# YT9215 register map
Vendor: Motorcomm; Series: YT921x; File version: 1.0
Motorcomm YT921x Gigabit Ethernet switch family, YT9215 family (YT9215SC, YT9215S, YT9215RB, YT9214NB, YT9213NB). The addresses are those of the switch register space, which a host reaches indirectly over MDIO; they are not memory mapped.
Registers are 32-bit, read-write, no defined reset value unless marked. A register's access mark holds for its fields unless they carry their own. Offsets are from the block's base; lines under a group give offsets from that group; [hi:lo] are bit positions; {n}, {i} and the like mark numbered series; 'fields as' and 'values as' point back to an identical list; <NAME> marks a mode.

## Memory map
0x0006A000 EXT_MBUS size 0x10 — External MDIO master
0x00080000 GLOBAL size 0xB00C — Global control and port MACs
0x000A0000 EEE_MAC size 0x284 — Per-port EEE
0x000B0000 EEE size 0x4 — EEE control
0x000C0000 MIB size 0xC00 — Port counters
0x000D0000 LED size 0x1F8 — LED control
0x000E0000 EDATA size 0x44 — Configuration byte store and clock
0x000F0000 INT_MBUS size 0x10 — Internal MDIO master
0x00100000 EGRESS size 0x310 — Egress tag processing
0x00180000 L2 size 0x10000 — Layer 2 forwarding and VLAN table
0x001C0000 ACL_ACTION size 0x17FC — ACL action table
0x00200000 ACL size 0x5F80 — ACL keys and control
0x00210000 PARSER size 0xD4 — Ingress parser
0x00220000 METER size 0x1258 — Ingress meters
0x00230000 PORT_VLAN size 0xAC — Ingress port VLAN
0x00300000 QUEUE size 0x304 — Queue manager
0x00340000 SCHED size 0x1602C — Egress scheduler

## EXT_MBUS — External MDIO master
Base 0x0006A000
0x00 EXT_MBUS_OP — Starts a transfer on the external MDIO master and shows when it has finished; see MDIO master transfer.
  [0] START — Write 1 to start the transfer set up in EXT_MBUS_CTRL. Reads 1 until the transfer is complete.
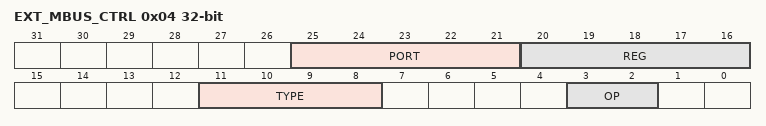
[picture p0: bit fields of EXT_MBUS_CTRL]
0x04 EXT_MBUS_CTRL — Address and direction of the next transfer on the external MDIO pins.
  [25:21] PORT — PHY address from 0 to 31. On the internal bus it equals the port number.
  [20:16] REG — PHY register number from 0 to 31.
  [11:8] TYPE — Frame format. The comment on the field reads "wild guess", so the width of the field is inferred.
    4=C22 (IEEE 802.3 clause 22 frame)
  [3:2] OP — Direction. The comment on the field reads "wild guess", so the width of the field is inferred.
    1=WRITE (Write the register); 2=READ (Read the register)
0x08 EXT_MBUS_DOUT — Data for the next write transfer on the external MDIO master.
  [15:0] DATA — The 16-bit PHY register value.
0x0C EXT_MBUS_DIN ro — Data returned by the last read transfer on the external MDIO master.
  [15:0] DATA — The 16-bit PHY register value.

## EEE_MAC — Per-port EEE
Base 0x000A0000
{0x0+0x40*i} EEE_VAL[{i}] (i=0..10) — Per-port Energy Efficient Ethernet bit that yt921x_set_eee sets and clears together with EEE_CTRL.EN of the port. It is not known what the bit does alone. Index: port = 0 to 10.
  [1] DATA — Set to turn Energy Efficient Ethernet on for the port and cleared to turn it off, as yt921x_set_eee does.

## EEE — EEE control
Base 0x000B0000
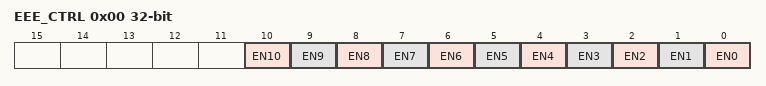
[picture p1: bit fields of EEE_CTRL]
0x00 EEE_CTRL — One Energy Efficient Ethernet enable bit per port; see Energy Efficient Ethernet.
  [n] EN{n} (n=0..10) — Enables Energy Efficient Ethernet on port port.

## MIB — Port counters
Base 0x000C0000
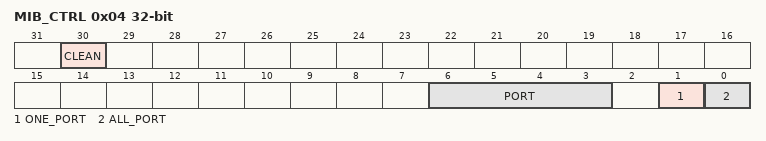
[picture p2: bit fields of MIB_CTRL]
0x04 MIB_CTRL — Clears port counters.
  [30] CLEAN — Write 1 to clear the selected counters.
  [6:3] PORT — Port whose counters are cleared when MIB_CTRL.ONE_PORT is set.
  [1] ONE_PORT — Clear the counters of the port in MIB_CTRL.PORT.
  [0] ALL_PORT — It is inferred from the name that the bit clears the counters of every port. The vendor SDK function fal_tiger_stat_mib_clear_all() leaves the bit at 0 for a clear of every port.
{0x100+0x100*i} MIB[{i}] (i=0..10) group — Counters of one port. Start of the counter block of one port. Each counter sits at a fixed byte offset inside the block, listed in Port counters.
  0x00 RX_BROADCAST ro — Broadcast frames received
  0x04 RX_PAUSE ro — Pause frames received
  0x08 RX_MULTICAST ro — Multicast frames received
  0x0C RX_CRC_ERR ro — Frames received with a bad frame check sequence
  0x10 RX_ALIGN_ERR ro — Frames received with an alignment error
  0x14 RX_UNDERSIZE_ERR ro — Frames received shorter than 64 bytes with a good frame check sequence
  0x18 RX_FRAG_ERR ro — Frames received shorter than 64 bytes with a bad frame check sequence
  0x1C RX_PKT_SZ_64 ro — Frames received with a length of 64 bytes
  0x20 RX_PKT_SZ_65_TO_127 ro — Frames received with a length of 65 to 127 bytes
  0x24 RX_PKT_SZ_128_TO_255 ro — Frames received with a length of 128 to 255 bytes
  0x28 RX_PKT_SZ_256_TO_511 ro — Frames received with a length of 256 to 511 bytes
  0x2C RX_PKT_SZ_512_TO_1023 ro — Frames received with a length of 512 to 1023 bytes
  0x30 RX_PKT_SZ_1024_TO_1518 ro — Frames received with a length of 1024 to 1518 bytes
  0x34 RX_PKT_SZ_1519_TO_MAX ro — Frames received longer than 1518 bytes
  0x3C RX_GOOD_BYTES 64-bit ro — Bytes received in good frames
  0x44 RX_BAD_BYTES 64-bit ro — Bytes received in bad frames
  0x4C RX_OVERSIZE_ERR ro — Frames received longer than the frame size limit
  0x50 RX_DROPPED ro — Received frames dropped by the switch
  0x54 TX_BROADCAST ro — Broadcast frames sent
  0x58 TX_PAUSE ro — Pause frames sent
  0x5C TX_MULTICAST ro — Multicast frames sent
  0x60 TX_UNDERSIZE_ERR ro — Frames sent shorter than 64 bytes
  0x64 TX_PKT_SZ_64 ro — Frames sent with a length of 64 bytes
  0x68 TX_PKT_SZ_65_TO_127 ro — Frames sent with a length of 65 to 127 bytes
  0x6C TX_PKT_SZ_128_TO_255 ro — Frames sent with a length of 128 to 255 bytes
  0x70 TX_PKT_SZ_256_TO_511 ro — Frames sent with a length of 256 to 511 bytes
  0x74 TX_PKT_SZ_512_TO_1023 ro — Frames sent with a length of 512 to 1023 bytes
  0x78 TX_PKT_SZ_1024_TO_1518 ro — Frames sent with a length of 1024 to 1518 bytes
  0x7C TX_PKT_SZ_1519_TO_MAX ro — Frames sent longer than 1518 bytes
  0x84 TX_GOOD_BYTES 64-bit ro — Bytes sent in good frames
  0x8C TX_COLLISION ro — Collisions seen while sending
  0x90 TX_EXCESSIVE_COLLISION ro — Frames not sent after 16 collisions
  0x94 TX_MULTIPLE_COLLISION ro — Frames sent after more than one collision
  0x98 TX_SINGLE_COLLISION ro — Frames sent after exactly one collision
  0x9C TX_PKT ro — Good frames sent
  0xA0 TX_DEFERRED ro — Frames whose first transmit attempt was deferred
  0xA4 TX_LATE_COLLISION ro — Collisions seen later than 512 bit times into a frame
  0xA8 RX_OAM ro — OAM frames received
  0xAC TX_OAM ro — OAM frames sent
